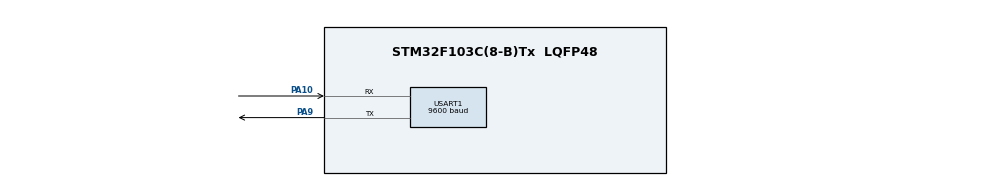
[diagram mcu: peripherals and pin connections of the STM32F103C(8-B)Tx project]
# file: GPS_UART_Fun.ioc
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Mcu.Family=STM32F1
Mcu.Name=STM32F103C(8-B)Tx
Mcu.Package=LQFP48
NVIC.PriorityGroup=NVIC_PRIORITYGROUP_4
NVIC.USART1_IRQn=true\:0\:0\:false\:false\:true\:true\:true\:true
PA10.Mode=Asynchronous
PA10.Signal=USART1_RX
PA9.Mode=Asynchronous
PA9.Signal=USART1_TX
ProjectManager.HeapSize=0x200
ProjectManager.StackSize=0x400
ProjectManager.TargetToolchain=STM32CubeIDE
RCC.APB1Freq_Value=8000000
RCC.APB2Freq_Value=8000000
USART1.BaudRate=9600
USART1.VirtualMode=VM_ASYNC
board=custom

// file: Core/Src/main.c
/* USER CODE BEGIN Header */
/**
  ******************************************************************************
  * @file           : main.c
  * @brief          : Main program body
  ******************************************************************************
  * @attention
  *
  * Copyright (c) 2024 STMicroelectronics.
  * All rights reserved.
  *
  * This software is licensed under terms that can be found in the LICENSE file
  * in the root directory of this software component.
  * If no LICENSE file comes with this software, it is provided AS-IS.
  *
  ******************************************************************************
  */
/* USER CODE END Header */
#include "main.h"

UART_HandleTypeDef huart1;

/* USER CODE BEGIN PV */

uint8_t Rx_data[10];  //  creating a buffer of 10 bytes

volatile unsigned char Gpsdata;    // for incoming serial data
unsigned int finish = 0;            // indicate end of message
unsigned int pos_cnt=0;            // position counter
unsigned int lat_cnt = 0;            // latitude data counter
unsigned int log_cnt = 0;            // longitude data counter
unsigned int flg    =0;            // GPS flag
unsigned int com_cnt=0;            // comma counter
unsigned char lat[20];             // latitude array
unsigned char lg[20];              // longitude array
int i=0;
unsigned char dir,dir1;

/* USER CODE END PV */

void SystemClock_Config(void);
static void MX_GPIO_Init(void);
static void MX_USART1_UART_Init(void);

int main(void)
{

  /* MCU Configuration--------------------------------------------------------*/

  /* Reset of all peripherals, Initializes the Flash interface and the Systick. */
  HAL_Init();

  /* Configure the system clock */
  SystemClock_Config();

  /* Initialize all configured peripherals */
  MX_GPIO_Init();
  MX_USART1_UART_Init();
  /* USER CODE BEGIN 2 */
  HAL_UART_Receive_IT(&huart1, Rx_data, 1);
  /* USER CODE END 2 */

  /* Infinite loop */
  while (1)
  {
	  HAL_Delay(10000);
  }
}

void SystemClock_Config(void)
{
  RCC_OscInitTypeDef RCC_OscInitStruct = {0};
  RCC_ClkInitTypeDef RCC_ClkInitStruct = {0};

  /** Initializes the RCC Oscillators according to the specified parameters
  * in the RCC_OscInitTypeDef structure.
  */
  RCC_OscInitStruct.OscillatorType = RCC_OSCILLATORTYPE_HSI;
  RCC_OscInitStruct.HSIState = RCC_HSI_ON;
  RCC_OscInitStruct.HSICalibrationValue = RCC_HSICALIBRATION_DEFAULT;
  RCC_OscInitStruct.PLL.PLLState = RCC_PLL_NONE;
  if (HAL_RCC_OscConfig(&RCC_OscInitStruct) != HAL_OK)
  {
    Error_Handler();
  }

  /** Initializes the CPU, AHB and APB buses clocks
  */
  RCC_ClkInitStruct.ClockType = RCC_CLOCKTYPE_HCLK|RCC_CLOCKTYPE_SYSCLK
                              |RCC_CLOCKTYPE_PCLK1|RCC_CLOCKTYPE_PCLK2;
  RCC_ClkInitStruct.SYSCLKSource = RCC_SYSCLKSOURCE_HSI;
  RCC_ClkInitStruct.AHBCLKDivider = RCC_SYSCLK_DIV1;
  RCC_ClkInitStruct.APB1CLKDivider = RCC_HCLK_DIV1;
  RCC_ClkInitStruct.APB2CLKDivider = RCC_HCLK_DIV1;

  if (HAL_RCC_ClockConfig(&RCC_ClkInitStruct, FLASH_LATENCY_0) != HAL_OK)
  {
    Error_Handler();
  }
}

static void MX_USART1_UART_Init(void)
{

  huart1.Instance = USART1;
  huart1.Init.BaudRate = 9600;
  huart1.Init.WordLength = UART_WORDLENGTH_8B;
  huart1.Init.StopBits = UART_STOPBITS_1;
  huart1.Init.Parity = UART_PARITY_NONE;
  huart1.Init.Mode = UART_MODE_TX_RX;
  huart1.Init.HwFlowCtl = UART_HWCONTROL_NONE;
  huart1.Init.OverSampling = UART_OVERSAMPLING_16;
  if (HAL_UART_Init(&huart1) != HAL_OK)
  {
    Error_Handler();
  }

}

static void MX_GPIO_Init(void)
{

  /* GPIO Ports Clock Enable */
  __HAL_RCC_GPIOA_CLK_ENABLE();

}

/* USER CODE BEGIN 4 */
void HAL_UART_RxCpltCallback(UART_HandleTypeDef *huart)
{
	Gpsdata = Rx_data[0];
	flg = 1;

	if(finish == 0){
		//check for #GPRMC which specifies the message type
			if (Gpsdata == '$' && pos_cnt == 0) {
				pos_cnt = 1;
			}
			if (Gpsdata == 'G' && pos_cnt == 1) {
				pos_cnt = 2;
			}
			if (Gpsdata == 'P' && pos_cnt == 2) {
				pos_cnt = 3;
			}
			if (Gpsdata == 'R' && pos_cnt == 3) {
				pos_cnt = 4;
			}
			if (Gpsdata == 'M' && pos_cnt == 4) {
				pos_cnt = 5;
			}
			if (Gpsdata == 'C' && pos_cnt == 5) {
				pos_cnt = 6;
			}
			if (pos_cnt == 6 && Gpsdata == ',') { // count commas in message
		        com_cnt++;
		        flg = 0;
			}
			if(Gpsdata=='N'||Gpsdata=='S'){dir=Gpsdata;}
			if(Gpsdata=='E'||Gpsdata=='W'){dir1=Gpsdata;}

			if (com_cnt == 3 && flg == 1) {
		            lat[lat_cnt++] = Gpsdata; // latitude
		            flg = 0;
		    }
			if (com_cnt == 5 && flg == 1) {
		            lg[log_cnt++] = Gpsdata; // longitude
		            flg = 0;
		    }
			if (Gpsdata == '*' && com_cnt >= 5 && flg == 1) {
		                lat[lat_cnt] = dir;
		                lat[lat_cnt + 1] = '\0'; // end of GPRMC message
		                lg[log_cnt] = dir1;
		                lg[log_cnt + 1] = '\0';
		                lat_cnt = 0;
		                log_cnt = 0;
		                flg = 0;
		                finish = 1;
		                com_cnt = 0;
		                i = 0;
		    }
	}

	HAL_UART_Receive_IT(&huart1, Rx_data, 1);
}
/* USER CODE END 4 */

void Error_Handler(void)
{
  __disable_irq();
  while (1)
  {
  }
}
